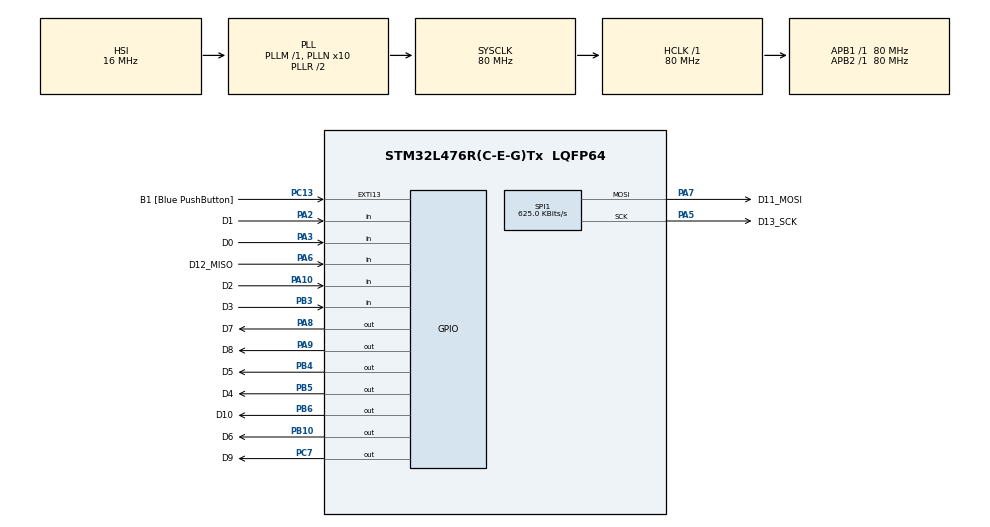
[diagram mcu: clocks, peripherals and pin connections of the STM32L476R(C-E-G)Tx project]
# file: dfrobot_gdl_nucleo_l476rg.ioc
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Mcu.Family=STM32L4
Mcu.Name=STM32L476R(C-E-G)Tx
Mcu.Package=LQFP64
NVIC.PriorityGroup=NVIC_PRIORITYGROUP_4
PA10.GPIO_Label=D2
PA10.GPIO_PuPd=GPIO_PULLDOWN
PA10.Signal=GPIO_Input
PA13\ (JTMS-SWDIO).GPIO_Label=TMS
PA13\ (JTMS-SWDIO).Mode=Serial_Wire
PA13\ (JTMS-SWDIO).Signal=SYS_JTMS-SWDIO
PA14\ (JTCK-SWCLK).GPIO_Label=TCK
PA14\ (JTCK-SWCLK).Mode=Serial_Wire
PA14\ (JTCK-SWCLK).Signal=SYS_JTCK-SWCLK
PA2.GPIO_Label=D1
PA2.GPIO_PuPd=GPIO_PULLDOWN
PA2.Signal=GPIO_Input
PA3.GPIO_Label=D0
PA3.GPIO_PuPd=GPIO_PULLDOWN
PA3.Signal=GPIO_Input
PA5.GPIO_Label=D13_SCK
PA5.Mode=TX_Only_Simplex_Unidirect_Master
PA5.Signal=SPI1_SCK
PA6.GPIO_Label=D12_MISO
PA6.Signal=GPIO_Input
PA7.GPIO_Label=D11_MOSI
PA7.Mode=TX_Only_Simplex_Unidirect_Master
PA7.Signal=SPI1_MOSI
PA8.GPIO_Label=D7
PA8.PinState=GPIO_PIN_SET
PA8.Signal=GPIO_Output
PA9.GPIO_Label=D8
PA9.Signal=GPIO_Output
PB10.GPIO_Label=D6
PB10.PinState=GPIO_PIN_SET
PB10.Signal=GPIO_Output
PB3\ (JTDO-TRACESWO).GPIO_Label=D3
PB3\ (JTDO-TRACESWO).Signal=GPIO_Input
PB4\ (NJTRST).GPIO_Label=D5
PB4\ (NJTRST).PinState=GPIO_PIN_SET
PB4\ (NJTRST).Signal=GPIO_Output
PB5.GPIO_Label=D4
PB5.GPIO_PuPd=GPIO_NOPULL
PB5.PinState=GPIO_PIN_SET
PB5.Signal=GPIO_Output
PB6.GPIO_Label=D10
PB6.GPIO_PuPd=GPIO_NOPULL
PB6.Signal=GPIO_Output
PC13.GPIO_Label=B1 [Blue PushButton]
PC13.GPIO_ModeDefaultEXTI=GPIO_MODE_IT_FALLING
PC13.GPIO_PuPd=GPIO_NOPULL
PC13.Signal=GPXTI13
PC14-OSC32_IN\ (PC14).Mode=LSE-External-Oscillator
PC14-OSC32_IN\ (PC14).Signal=RCC_OSC32_IN
PC15-OSC32_OUT\ (PC15).Mode=LSE-External-Oscillator
PC15-OSC32_OUT\ (PC15).Signal=RCC_OSC32_OUT
PC7.GPIO_Label=D9
PC7.Signal=GPIO_Output
PH0-OSC_IN\ (PH0).Signal=RCC_OSC_IN
PH1-OSC_OUT\ (PH1).Signal=RCC_OSC_OUT
ProjectManager.HeapSize=0x2000
ProjectManager.StackSize=0x4000
ProjectManager.TargetToolchain=STM32CubeIDE
RCC.ADCFreq_Value=64000000
RCC.AHBFreq_Value=80000000
RCC.APB1Freq_Value=80000000
RCC.APB1TimFreq_Value=80000000
RCC.APB2Freq_Value=80000000
RCC.APB2TimFreq_Value=80000000
RCC.CortexFreq_Value=80000000
RCC.HCLKFreq_Value=80000000
RCC.HSE_VALUE=8000000
RCC.HSI_VALUE=16000000
RCC.MSI_VALUE=4000000
RCC.PLLN=10
RCC.PLLSourceVirtual=RCC_PLLSOURCE_HSI
RCC.PREFETCH_ENABLE=1
RCC.SYSCLKFreq_VALUE=80000000
RCC.SYSCLKSource=RCC_SYSCLKSOURCE_PLLCLK
RCC.USBFreq_Value=64000000
RCC.VCOOutputFreq_Value=160000000
SPI1.BaudRatePrescaler=SPI_BAUDRATEPRESCALER_128
SPI1.CalculateBaudRate=625.0 KBits/s
SPI1.DataSize=SPI_DATASIZE_8BIT
SPI1.Direction=SPI_DIRECTION_2LINES
SPI1.Mode=SPI_MODE_MASTER
SPI1.NSSPMode=SPI_NSS_PULSE_DISABLE
SPI1.VirtualType=VM_MASTER
TIM6.Period=40000-1
TIM6.Prescaler=2-1
VP_TIM6_VS_ClockSourceINT.Mode=Enable_Timer
board=NUCLEO-L476RG

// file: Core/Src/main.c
/* USER CODE BEGIN Header */
/**
  ******************************************************************************
  * @file           : main.c
  * @brief          : Main program body
  ******************************************************************************
  * @attention
  *
  * Copyright (c) 2023 STMicroelectronics.
  * All rights reserved.
  *
  * This software is licensed under terms that can be found in the LICENSE file
  * in the root directory of this software component.
  * If no LICENSE file comes with this software, it is provided AS-IS.
  *
  ******************************************************************************
  */
/* USER CODE END Header */
#include "main.h"
#include "spi.h"
#include "tim.h"
#include "gpio.h"

/* USER CODE BEGIN Includes */
#include "mainApp.h"
/* USER CODE END Includes */

void SystemClock_Config(void);

int main(void)
{

  /* MCU Configuration--------------------------------------------------------*/

  /* Reset of all peripherals, Initializes the Flash interface and the Systick. */
  HAL_Init();

  /* Configure the system clock */
  SystemClock_Config();

  /* Initialize all configured peripherals */
  MX_GPIO_Init();
  MX_SPI1_Init();
  MX_TIM6_Init();
  /* USER CODE BEGIN 2 */
  mainApp_init();
  /* USER CODE END 2 */

  /* Infinite loop */
  /* USER CODE BEGIN WHILE */
  while (1)
  {
    mainApp_task();
    /* USER CODE END WHILE */

  }
}

void SystemClock_Config(void)
{
  RCC_OscInitTypeDef RCC_OscInitStruct = {0};
  RCC_ClkInitTypeDef RCC_ClkInitStruct = {0};

  /** Configure the main internal regulator output voltage
  */
  if (HAL_PWREx_ControlVoltageScaling(PWR_REGULATOR_VOLTAGE_SCALE1) != HAL_OK)
  {
    Error_Handler();
  }

  /** Initializes the RCC Oscillators according to the specified parameters
  * in the RCC_OscInitTypeDef structure.
  */
  RCC_OscInitStruct.OscillatorType = RCC_OSCILLATORTYPE_HSI;
  RCC_OscInitStruct.HSIState = RCC_HSI_ON;
  RCC_OscInitStruct.HSICalibrationValue = RCC_HSICALIBRATION_DEFAULT;
  RCC_OscInitStruct.PLL.PLLState = RCC_PLL_ON;
  RCC_OscInitStruct.PLL.PLLSource = RCC_PLLSOURCE_HSI;
  RCC_OscInitStruct.PLL.PLLM = 1;
  RCC_OscInitStruct.PLL.PLLN = 10;
  RCC_OscInitStruct.PLL.PLLP = RCC_PLLP_DIV7;
  RCC_OscInitStruct.PLL.PLLQ = RCC_PLLQ_DIV2;
  RCC_OscInitStruct.PLL.PLLR = RCC_PLLR_DIV2;
  if (HAL_RCC_OscConfig(&RCC_OscInitStruct) != HAL_OK)
  {
    Error_Handler();
  }

  /** Initializes the CPU, AHB and APB buses clocks
  */
  RCC_ClkInitStruct.ClockType = RCC_CLOCKTYPE_HCLK|RCC_CLOCKTYPE_SYSCLK
                              |RCC_CLOCKTYPE_PCLK1|RCC_CLOCKTYPE_PCLK2;
  RCC_ClkInitStruct.SYSCLKSource = RCC_SYSCLKSOURCE_PLLCLK;
  RCC_ClkInitStruct.AHBCLKDivider = RCC_SYSCLK_DIV1;
  RCC_ClkInitStruct.APB1CLKDivider = RCC_HCLK_DIV1;
  RCC_ClkInitStruct.APB2CLKDivider = RCC_HCLK_DIV1;

  if (HAL_RCC_ClockConfig(&RCC_ClkInitStruct, FLASH_LATENCY_4) != HAL_OK)
  {
    Error_Handler();
  }
}

void Error_Handler(void)
{
  __disable_irq();
  while (1)
  {
  }
}
